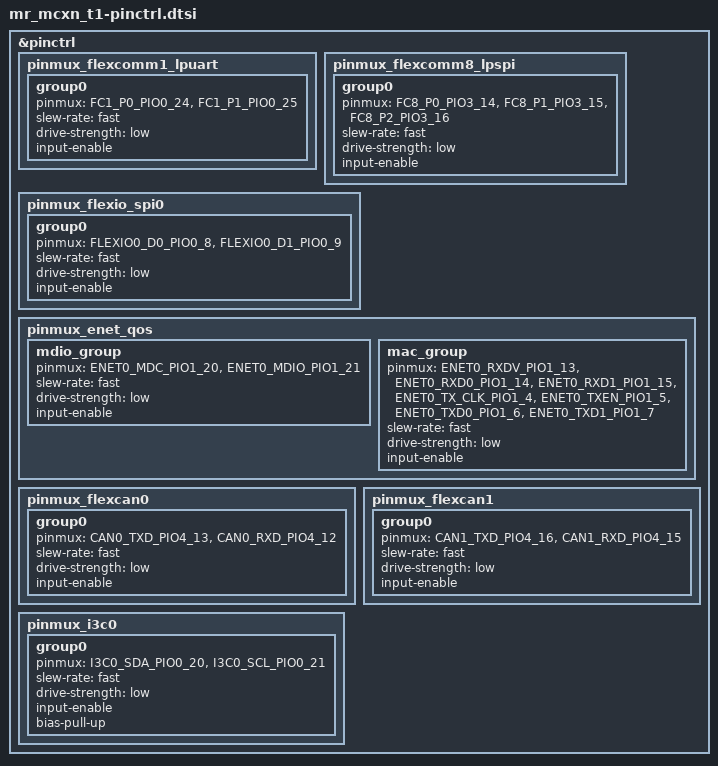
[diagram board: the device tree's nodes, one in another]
/*
 * Copyright 2024 NXP
 * SPDX-License-Identifier: Apache-2.0
 */


#include <nxp/mcx/MCXN947VDF-pinctrl.h>

&pinctrl {
	pinmux_flexcomm1_lpuart: pinmux_flexcomm1_lpuart {
		group0 {
			pinmux = <FC1_P0_PIO0_24>,
				<FC1_P1_PIO0_25>;
			slew-rate = "fast";
			drive-strength = "low";
			input-enable;
		};
	};
	
	pinmux_flexcomm8_lpspi: pinmux_flexcomm8_lpspi {
		group0 {
			pinmux = <FC8_P0_PIO3_14>,
				<FC8_P1_PIO3_15>,
				<FC8_P2_PIO3_16>;
				/*<FC8_P3_PIO3_17>; CS */ 
			slew-rate = "fast";
			drive-strength = "low";
			input-enable;
		};
	};

	pinmux_flexio_spi0: pinmux_flexio_spi0 {
		group0 {
			pinmux = <FLEXIO0_D0_PIO0_8>,
				<FLEXIO0_D1_PIO0_9>;
			slew-rate = "fast";
			drive-strength = "low";
			input-enable;
		};
	};

	pinmux_enet_qos: pinmux_enet_qos {
		mdio_group {
			pinmux = <ENET0_MDC_PIO1_20>,
				<ENET0_MDIO_PIO1_21>;
			slew-rate = "fast";
			drive-strength = "low";
			input-enable;
		};
		mac_group {
			pinmux = <ENET0_RXDV_PIO1_13>,
				<ENET0_RXD0_PIO1_14>,
				<ENET0_RXD1_PIO1_15>,
				<ENET0_TX_CLK_PIO1_4>,
				<ENET0_TXEN_PIO1_5>,
				<ENET0_TXD0_PIO1_6>,
				<ENET0_TXD1_PIO1_7>;
			slew-rate = "fast";
			drive-strength = "low";
			input-enable;
		};
	};

	pinmux_flexcan0: pinmux_flexcan0 {
		group0 {
			pinmux = <CAN0_TXD_PIO4_13>,
				<CAN0_RXD_PIO4_12>;
			slew-rate = "fast";
			drive-strength = "low";
			input-enable;
		};
	};

	pinmux_flexcan1: pinmux_flexcan1 {
		group0 {
			pinmux = <CAN1_TXD_PIO4_16>,
				<CAN1_RXD_PIO4_15>;
			slew-rate = "fast";
			drive-strength = "low";
			input-enable;
		};
	};

	pinmux_i3c0: pinmux_i3c0 {
		group0 {
			pinmux = <I3C0_SDA_PIO0_20>,
				<I3C0_SCL_PIO0_21>;
			slew-rate = "fast";
			drive-strength = "low";
			input-enable;
			bias-pull-up;
		};
	};

};
